# STM32L412xx register map
File version: 1.0
Registers are 32-bit, read-write, reset 0x0 unless marked. A register's access mark holds for its fields unless they carry their own. Offsets are from the block's base; [hi:lo] are bit positions; {n}, {i} and the like mark numbered series.

## OPAMP — Operational Amplifier (OPAMP)
Base 0x40007800
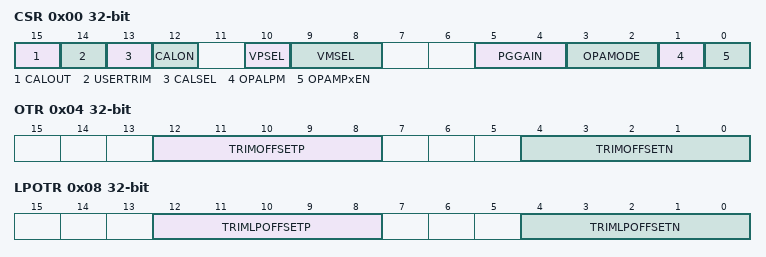
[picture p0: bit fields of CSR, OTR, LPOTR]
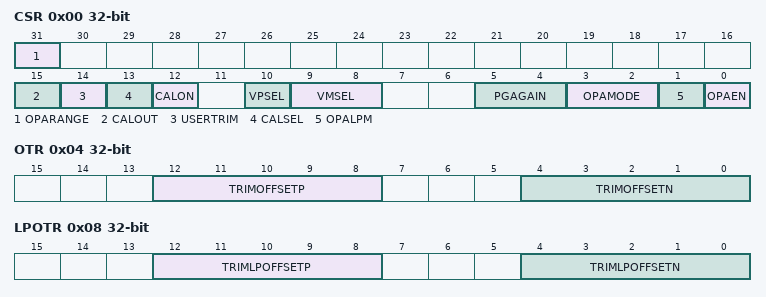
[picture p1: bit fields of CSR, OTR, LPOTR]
0x00 CSR — OPAMP control/status register
  [15] CALOUT — Operational amplifier1 calibration output
  [14] USERTRIM — User trimming enable
    0=FACTORY (OPAMP trimming factors set to factory values); 1=USER (OPAMP trimming factors set to user values)
  [13] CALSEL — Calibration selection
  [12] CALON — Calibration mode enable
    0=FUNCTIONAL (OPAMP functional mode); 1=CALIBRATION (OPAMP calibration mode)
  [10] VPSEL — Non inverted input selection
    0=NONINVERT_IO0 (OPAMP non inverting input connected to GPIO pin (pin PA0 for OPAMP1, pin PA6 for OPAMP2)); 1=NONINV_DAC1_CH1 (OPAMP non inverting input connected to DAC1 channel1 output)
  [9:8] VMSEL — Inverting input selection
    0=IO0 (OPAMP inverting input connected to GPIO pin (valid also in PGA mode for filtering). Note: OPAMP inverting input is used with OPAMP in mode standalone or PGA with external capacitors for filtering circuit. Otherwise (OPAMP in mode follower), OPAMP inverting input is not used (not connected to GPIO pin).); 1=IO1 (OPAMP inverting input (low leakage input) connected to GPIO pin (available only on package BGA132). Note: OPAMP inverting input is used with OPAMP in mode standalone or PGA with external capacitors for filtering circuit. Otherwise (OPAMP in mode follower), OPAMP inverting input is not used (not connected to GPIO pin).); 2=CONNECT_NO (OPAMP inverting input not externally connected (intended for OPAMP in mode follower or PGA without external capacitors for filtering))
  [5:4] PGGAIN — Operational amplifier Programmable amplifier gain value
    0=GAIN_2 (OPAMP PGA gain 2); 1=GAIN_4 (OPAMP PGA gain 4); 2=GAIN_8 (OPAMP PGA gain 8); 3=GAIN_16 (OPAMP PGA gain 16)
  [3:2] OPAMODE — Operational amplifier PGA mode
    0=STANDALONE (OPAMP functional mode, OPAMP operation in standalone); 3=FOLLOWER (OPAMP functional mode, OPAMP operation in follower); 2=PGA (OPAMP functional mode, OPAMP operation in PGA)
  [1] OPALPM — Operational amplifier Low Power Mode
  [0] OPAMPxEN — OPAMP enable
0x04 OTR — OPAMP
  [12:8] TRIMOFFSETP — Trim for PMOS differential pairs
  [4:0] TRIMOFFSETN — Trim for NMOS differential pairs
0x08 LPOTR — OPAMP
  [12:8] TRIMLPOFFSETP — Trim for PMOS differential pairs
  [4:0] TRIMLPOFFSETN — Trim for NMOS differential pairs

## OPAMP1 — Operational Amplifier (OPAMP)
Base 0x40007800; alternate view of OPAMP
0x00 CSR — OPAMP control/status register
  [31] OPARANGE — Common to several OPAMP instances: Operational amplifier voltage supply range. Bit intended to be used with OPAMP common instance (OPAMP_Common_TypeDef)
    0=LOW (Power supply range low. On STM32L4 series: Vdda lower than 2.4V.); 1=HIGH (Power supply range high. On STM32L4 series: Vdda higher than 2.4V.)
  [15] CALOUT — Operational amplifier1 calibration output
  [14] USERTRIM — User trimming enable
  [13] CALSEL — Calibration selection
  [12] CALON — Calibration mode enable
  [10] VPSEL — Non inverted input selection
  [9:8] VMSEL — Inverting input selection
  [5:4] PGAGAIN — Operational amplifier1 Programmable amplifier gain value
  [3:2] OPAMODE — Operational amplifier1 PGA mode
  [1] OPALPM — Operational amplifier1 Low Power Mode
  [0] OPAEN — Operational amplifier1 Enable
0x04 OTR — OPAMP
  [12:8] TRIMOFFSETP — Trim for PMOS differential pairs
  [4:0] TRIMOFFSETN — Trim for NMOS differential pairs
0x08 LPOTR — OPAMP
  [12:8] TRIMLPOFFSETP — Trim for PMOS differential pairs
  [4:0] TRIMLPOFFSETN — Trim for NMOS differential pairs

## SYSCFG — System configuration controller
Base 0x40010000
0x00 MEMRMP — SYSCFG memory remap register
  [2:0] MEM_MODE — SYSCFG_Memory Remap Config
    0=FLASH (Main Flash memory mapped at 0x00000000); 1=SYSTEMFLASH (System Flash memory mapped at 0x00000000); 3=SRAM (SRAM1 mapped at 0x00000000); 6=QUADSPI (QUADSPI memory mapped at 0x00000000)
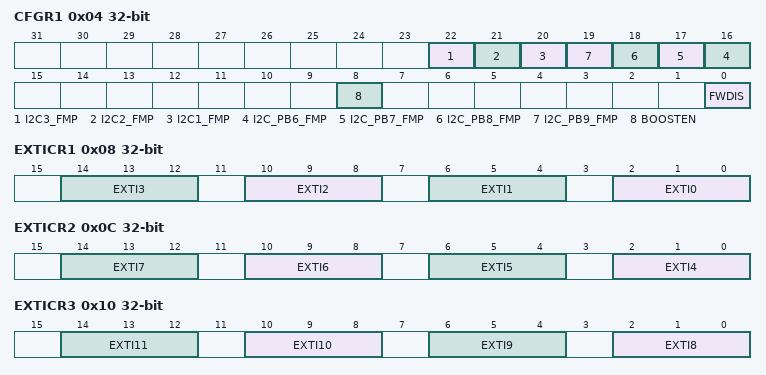
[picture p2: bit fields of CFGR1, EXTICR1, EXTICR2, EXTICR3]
0x04 CFGR1 — SYSCFG configuration register 1
  [22] I2C3_FMP — I2C3 Fast mode plus
  [21] I2C2_FMP — I2C2 Fast mode plus
  [20] I2C1_FMP — I2C1 Fast mode plus
  [n+10] I2C_PB{n}_FMP (n=6..9) — I2C PB{n} Fast mode plus
  [8] BOOSTEN — I/O analog switch voltage booster enable
  [0] FWDIS — FIREWALL access enable
0x08 EXTICR1 — SYSCFG external interrupt configuration registers
  [4n+2:4n] EXTI{n} (n=0..3) — EXTI {n} configuration
0x0C EXTICR2 — SYSCFG external interrupt configuration registers
  [4n-14:4n-16] EXTI{n} (n=4..7) — EXTI {n} configuration
0x10 EXTICR3 — SYSCFG external interrupt configuration registers
  [4n-30:4n-32] EXTI{n} (n=8..11) — EXTI {n} configuration
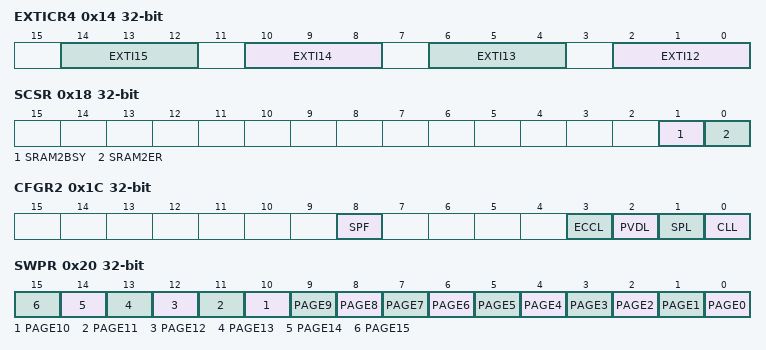
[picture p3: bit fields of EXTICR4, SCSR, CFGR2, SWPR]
0x14 EXTICR4 — SYSCFG external interrupt configuration registers
  [4n-46:4n-48] EXTI{n} (n=12..15) — EXTI {n} configuration
0x18 SCSR — SYSCFG SRAM2 control and status register
  [1] SRAM2BSY — SRAM2 Erase Ongoing
  [0] SRAM2ER — SRAM2 Erase Request
0x1C CFGR2 — SYSCFG configuration register 2
  [8] SPF — SRAM Parity Flag
  [3] ECCL — ECC Lock
  [2] PVDL — PVD Lock
  [1] SPL — SRAM Parity Lock
  [0] CLL — Core Lockup Lock
0x20 SWPR — SYSCFG SRAM2 write protection register
  [n] PAGE{n} (n=0..15) — SRAM2 Write protection page {n}
0x24 SKR — SYSCFG SRAM2 key register
  [7:0] KEY — SRAM2 write protection key for software erase
